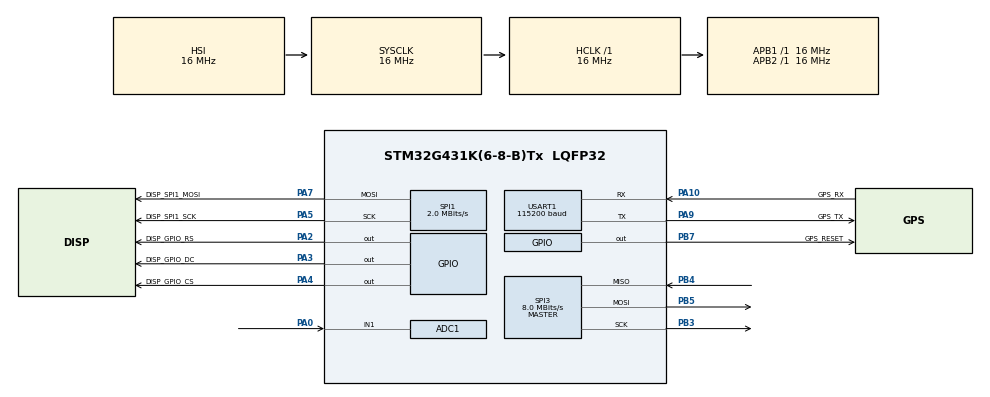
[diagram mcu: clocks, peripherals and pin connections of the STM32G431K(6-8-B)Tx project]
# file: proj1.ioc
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ADC1.Channel-0\#ChannelRegularConversion=ADC_CHANNEL_1
ADC1.NbrOfConversionFlag=1
ADC1.OffsetNumber-0\#ChannelRegularConversion=ADC_OFFSET_NONE
ADC1.Rank-0\#ChannelRegularConversion=1
ADC1.SamplingTime-0\#ChannelRegularConversion=ADC_SAMPLETIME_2CYCLES_5
ADC1.master=1
Dma.Request0=USART1_RX
Dma.USART1_RX.0.Direction=DMA_PERIPH_TO_MEMORY
Dma.USART1_RX.0.EventEnable=DISABLE
Dma.USART1_RX.0.Instance=DMA1_Channel1
Dma.USART1_RX.0.MemDataAlignment=DMA_MDATAALIGN_BYTE
Dma.USART1_RX.0.MemInc=DMA_MINC_ENABLE
Dma.USART1_RX.0.Mode=DMA_NORMAL
Dma.USART1_RX.0.PeriphDataAlignment=DMA_PDATAALIGN_BYTE
Dma.USART1_RX.0.PeriphInc=DMA_PINC_DISABLE
Dma.USART1_RX.0.Polarity=HAL_DMAMUX_REQ_GEN_RISING
Dma.USART1_RX.0.Priority=DMA_PRIORITY_LOW
Dma.USART1_RX.0.RequestNumber=1
Dma.USART1_RX.0.SignalID=NONE
Dma.USART1_RX.0.SyncEnable=DISABLE
Dma.USART1_RX.0.SyncPolarity=HAL_DMAMUX_SYNC_NO_EVENT
Dma.USART1_RX.0.SyncRequestNumber=1
Dma.USART1_RX.0.SyncSignalID=NONE
Mcu.Family=STM32G4
Mcu.Name=STM32G431K(6-8-B)Tx
Mcu.Package=LQFP32
NVIC.DMA1_Channel1_IRQn=true\:0\:0\:false\:false\:true\:false\:true\:true
NVIC.PriorityGroup=NVIC_PRIORITYGROUP_4
NVIC.USART1_IRQn=true\:0\:0\:false\:false\:true\:true\:true\:true
PA0.Mode=IN1-Single-Ended
PA0.Signal=ADC1_IN1
PA10.GPIO_Label=GPS_RX
PA10.Mode=Asynchronous
PA10.Signal=USART1_RX
PA13.Mode=Serial_Wire
PA13.Signal=SYS_JTMS-SWDIO
PA14.Mode=Serial_Wire
PA14.Signal=SYS_JTCK-SWCLK
PA2.GPIO_Label=DISP_GPIO_RS
PA2.Signal=GPIO_Output
PA3.GPIO_Label=DISP_GPIO_DC
PA3.Signal=GPIO_Output
PA4.GPIO_Label=DISP_GPIO_CS
PA4.Signal=GPIO_Output
PA5.GPIO_Label=DISP_SPI1_SCK
PA5.Mode=TX_Only_Simplex_Unidirect_Master
PA5.Signal=SPI1_SCK
PA7.GPIO_Label=DISP_SPI1_MOSI
PA7.Mode=TX_Only_Simplex_Unidirect_Master
PA7.Signal=SPI1_MOSI
PA9.GPIO_Label=GPS_TX
PA9.Mode=Asynchronous
PA9.Signal=USART1_TX
PB3.Mode=Full_Duplex_Master
PB3.Signal=SPI3_SCK
PB4.Mode=Full_Duplex_Master
PB4.Signal=SPI3_MISO
PB5.Mode=Full_Duplex_Master
PB5.Signal=SPI3_MOSI
PB7.GPIO_Label=GPS_RESET
PB7.Signal=GPIO_Output
ProjectManager.HeapSize=0x200
ProjectManager.StackSize=0x400
ProjectManager.TargetToolchain=STM32CubeIDE
RCC.AHBFreq_Value=16000000
RCC.APB1Freq_Value=16000000
RCC.APB1TimFreq_Value=16000000
RCC.APB2Freq_Value=16000000
RCC.APB2TimFreq_Value=16000000
RCC.CortexFreq_Value=16000000
RCC.EXTERNAL_CLOCK_VALUE=12288000
RCC.HCLKFreq_Value=16000000
RCC.HSE_VALUE=8000000
RCC.HSI48_VALUE=48000000
RCC.HSI_VALUE=16000000
RCC.LSE_VALUE=32768
RCC.SYSCLKFreq_VALUE=16000000
RCC.USBFreq_Value=64000000
RCC.VCOOutputFreq_Value=128000000
SPI1.BaudRatePrescaler=SPI_BAUDRATEPRESCALER_8
SPI1.CLKPhase=SPI_PHASE_2EDGE
SPI1.CLKPolarity=SPI_POLARITY_HIGH
SPI1.CalculateBaudRate=2.0 MBits/s
SPI1.DataSize=SPI_DATASIZE_8BIT
SPI1.Direction=SPI_DIRECTION_2LINES
SPI1.Mode=SPI_MODE_MASTER
SPI1.VirtualType=VM_MASTER
SPI3.CalculateBaudRate=8.0 MBits/s
SPI3.Direction=SPI_DIRECTION_2LINES
SPI3.Mode=SPI_MODE_MASTER
SPI3.VirtualType=VM_MASTER
USART1.BaudRate=115200
USART1.VirtualMode-Asynchronous=VM_ASYNC
VP_SYS_VS_DBSignals.Mode=DisableDeadBatterySignals
board=custom

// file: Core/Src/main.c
/* USER CODE BEGIN Header */
/**
  ******************************************************************************
  * @file           : main.c
  * @brief          : Main program body
  ******************************************************************************
  * @attention
  *
  * Copyright (c) 2025 STMicroelectronics.
  * All rights reserved.
  *
  * This software is licensed under terms that can be found in the LICENSE file
  * in the root directory of this software component.
  * If no LICENSE file comes with this software, it is provided AS-IS.
  *
  ******************************************************************************
  */
/* USER CODE END Header */
#include "main.h"
#include "display.h"
#include "gps.h"
#include "text.h"
#include "utils.h"

ADC_HandleTypeDef hadc1;

SPI_HandleTypeDef hspi1;
SPI_HandleTypeDef hspi3;

UART_HandleTypeDef huart1;
DMA_HandleTypeDef hdma_usart1_rx;

void SystemClock_Config(void);
static void MX_GPIO_Init(void);
static void MX_DMA_Init(void);
static void MX_ADC1_Init(void);
static void MX_SPI1_Init(void);
static void MX_SPI3_Init(void);
static void MX_USART1_UART_Init(void);

int main(void)
{

  /* MCU Configuration--------------------------------------------------------*/

  /* Reset of all peripherals, Initializes the Flash interface and the Systick. */
  HAL_Init();

  /* Configure the system clock */
  SystemClock_Config();

  /* Initialize all configured peripherals */
  MX_GPIO_Init();
  MX_DMA_Init();
  MX_ADC1_Init();
  MX_SPI1_Init();
  MX_SPI3_Init();
  MX_USART1_UART_Init();
  /* USER CODE BEGIN 2 */

  display_setup();

  display_clear();
  buffer_clear();

  origin_set(0, 0);

  writestr("GPS SUBSYS START..");
  initializeGPS();
  display_update();

  startAsyncReceive(1);
  /* USER CODE END 2 */

  /* Infinite loop */
  while (1)
  {
	  maincall();
  }
}

void SystemClock_Config(void)
{
  RCC_OscInitTypeDef RCC_OscInitStruct = {0};
  RCC_ClkInitTypeDef RCC_ClkInitStruct = {0};

  /** Configure the main internal regulator output voltage
  */
  HAL_PWREx_ControlVoltageScaling(PWR_REGULATOR_VOLTAGE_SCALE1);

  /** Initializes the RCC Oscillators according to the specified parameters
  * in the RCC_OscInitTypeDef structure.
  */
  RCC_OscInitStruct.OscillatorType = RCC_OSCILLATORTYPE_HSI;
  RCC_OscInitStruct.HSIState = RCC_HSI_ON;
  RCC_OscInitStruct.HSICalibrationValue = RCC_HSICALIBRATION_DEFAULT;
  RCC_OscInitStruct.PLL.PLLState = RCC_PLL_NONE;
  if (HAL_RCC_OscConfig(&RCC_OscInitStruct) != HAL_OK)
  {
    Error_Handler();
  }

  /** Initializes the CPU, AHB and APB buses clocks
  */
  RCC_ClkInitStruct.ClockType = RCC_CLOCKTYPE_HCLK|RCC_CLOCKTYPE_SYSCLK
                              |RCC_CLOCKTYPE_PCLK1|RCC_CLOCKTYPE_PCLK2;
  RCC_ClkInitStruct.SYSCLKSource = RCC_SYSCLKSOURCE_HSI;
  RCC_ClkInitStruct.AHBCLKDivider = RCC_SYSCLK_DIV1;
  RCC_ClkInitStruct.APB1CLKDivider = RCC_HCLK_DIV1;
  RCC_ClkInitStruct.APB2CLKDivider = RCC_HCLK_DIV1;

  if (HAL_RCC_ClockConfig(&RCC_ClkInitStruct, FLASH_LATENCY_0) != HAL_OK)
  {
    Error_Handler();
  }
}

static void MX_ADC1_Init(void)
{

  ADC_MultiModeTypeDef multimode = {0};
  ADC_ChannelConfTypeDef sConfig = {0};

  /** Common config
  */
  hadc1.Instance = ADC1;
  hadc1.Init.ClockPrescaler = ADC_CLOCK_SYNC_PCLK_DIV2;
  hadc1.Init.Resolution = ADC_RESOLUTION_12B;
  hadc1.Init.DataAlign = ADC_DATAALIGN_RIGHT;
  hadc1.Init.GainCompensation = 0;
  hadc1.Init.ScanConvMode = ADC_SCAN_DISABLE;
  hadc1.Init.EOCSelection = ADC_EOC_SINGLE_CONV;
  hadc1.Init.LowPowerAutoWait = DISABLE;
  hadc1.Init.ContinuousConvMode = DISABLE;
  hadc1.Init.NbrOfConversion = 1;
  hadc1.Init.DiscontinuousConvMode = DISABLE;
  hadc1.Init.ExternalTrigConv = ADC_SOFTWARE_START;
  hadc1.Init.ExternalTrigConvEdge = ADC_EXTERNALTRIGCONVEDGE_NONE;
  hadc1.Init.DMAContinuousRequests = DISABLE;
  hadc1.Init.Overrun = ADC_OVR_DATA_PRESERVED;
  hadc1.Init.OversamplingMode = DISABLE;
  if (HAL_ADC_Init(&hadc1) != HAL_OK)
  {
    Error_Handler();
  }

  /** Configure the ADC multi-mode
  */
  multimode.Mode = ADC_MODE_INDEPENDENT;
  if (HAL_ADCEx_MultiModeConfigChannel(&hadc1, &multimode) != HAL_OK)
  {
    Error_Handler();
  }

  /** Configure Regular Channel
  */
  sConfig.Channel = ADC_CHANNEL_1;
  sConfig.Rank = ADC_REGULAR_RANK_1;
  sConfig.SamplingTime = ADC_SAMPLETIME_2CYCLES_5;
  sConfig.SingleDiff = ADC_SINGLE_ENDED;
  sConfig.OffsetNumber = ADC_OFFSET_NONE;
  sConfig.Offset = 0;
  if (HAL_ADC_ConfigChannel(&hadc1, &sConfig) != HAL_OK)
  {
    Error_Handler();
  }

}

static void MX_SPI1_Init(void)
{

  /* SPI1 parameter configuration*/
  hspi1.Instance = SPI1;
  hspi1.Init.Mode = SPI_MODE_MASTER;
  hspi1.Init.Direction = SPI_DIRECTION_2LINES;
  hspi1.Init.DataSize = SPI_DATASIZE_8BIT;
  hspi1.Init.CLKPolarity = SPI_POLARITY_HIGH;
  hspi1.Init.CLKPhase = SPI_PHASE_2EDGE;
  hspi1.Init.NSS = SPI_NSS_SOFT;
  hspi1.Init.BaudRatePrescaler = SPI_BAUDRATEPRESCALER_8;
  hspi1.Init.FirstBit = SPI_FIRSTBIT_MSB;
  hspi1.Init.TIMode = SPI_TIMODE_DISABLE;
  hspi1.Init.CRCCalculation = SPI_CRCCALCULATION_DISABLE;
  hspi1.Init.CRCPolynomial = 7;
  hspi1.Init.CRCLength = SPI_CRC_LENGTH_DATASIZE;
  hspi1.Init.NSSPMode = SPI_NSS_PULSE_DISABLE;
  if (HAL_SPI_Init(&hspi1) != HAL_OK)
  {
    Error_Handler();
  }

}

static void MX_SPI3_Init(void)
{

  /* SPI3 parameter configuration*/
  hspi3.Instance = SPI3;
  hspi3.Init.Mode = SPI_MODE_MASTER;
  hspi3.Init.Direction = SPI_DIRECTION_2LINES;
  hspi3.Init.DataSize = SPI_DATASIZE_4BIT;
  hspi3.Init.CLKPolarity = SPI_POLARITY_LOW;
  hspi3.Init.CLKPhase = SPI_PHASE_1EDGE;
  hspi3.Init.NSS = SPI_NSS_SOFT;
  hspi3.Init.BaudRatePrescaler = SPI_BAUDRATEPRESCALER_2;
  hspi3.Init.FirstBit = SPI_FIRSTBIT_MSB;
  hspi3.Init.TIMode = SPI_TIMODE_DISABLE;
  hspi3.Init.CRCCalculation = SPI_CRCCALCULATION_DISABLE;
  hspi3.Init.CRCPolynomial = 7;
  hspi3.Init.CRCLength = SPI_CRC_LENGTH_DATASIZE;
  hspi3.Init.NSSPMode = SPI_NSS_PULSE_ENABLE;
  if (HAL_SPI_Init(&hspi3) != HAL_OK)
  {
    Error_Handler();
  }

}

static void MX_USART1_UART_Init(void)
{

  huart1.Instance = USART1;
  huart1.Init.BaudRate = 115200;
  huart1.Init.WordLength = UART_WORDLENGTH_8B;
  huart1.Init.StopBits = UART_STOPBITS_1;
  huart1.Init.Parity = UART_PARITY_NONE;
  huart1.Init.Mode = UART_MODE_TX_RX;
  huart1.Init.HwFlowCtl = UART_HWCONTROL_NONE;
  huart1.Init.OverSampling = UART_OVERSAMPLING_16;
  huart1.Init.OneBitSampling = UART_ONE_BIT_SAMPLE_DISABLE;
  huart1.Init.ClockPrescaler = UART_PRESCALER_DIV1;
  huart1.AdvancedInit.AdvFeatureInit = UART_ADVFEATURE_NO_INIT;
  if (HAL_UART_Init(&huart1) != HAL_OK)
  {
    Error_Handler();
  }
  if (HAL_UARTEx_SetTxFifoThreshold(&huart1, UART_TXFIFO_THRESHOLD_1_8) != HAL_OK)
  {
    Error_Handler();
  }
  if (HAL_UARTEx_SetRxFifoThreshold(&huart1, UART_RXFIFO_THRESHOLD_1_8) != HAL_OK)
  {
    Error_Handler();
  }
  if (HAL_UARTEx_DisableFifoMode(&huart1) != HAL_OK)
  {
    Error_Handler();
  }

}

static void MX_DMA_Init(void)
{

  /* DMA controller clock enable */
  __HAL_RCC_DMAMUX1_CLK_ENABLE();
  __HAL_RCC_DMA1_CLK_ENABLE();

  /* DMA interrupt init */
  /* DMA1_Channel1_IRQn interrupt configuration */
  HAL_NVIC_SetPriority(DMA1_Channel1_IRQn, 0, 0);
  HAL_NVIC_EnableIRQ(DMA1_Channel1_IRQn);

}

static void MX_GPIO_Init(void)
{
  GPIO_InitTypeDef GPIO_InitStruct = {0};

  /* GPIO Ports Clock Enable */
  __HAL_RCC_GPIOA_CLK_ENABLE();
  __HAL_RCC_GPIOB_CLK_ENABLE();

  /*Configure GPIO pin Output Level */
  HAL_GPIO_WritePin(GPIOA, DISP_GPIO_RS_Pin|DISP_GPIO_DC_Pin|DISP_GPIO_CS_Pin, GPIO_PIN_RESET);

  /*Configure GPIO pin Output Level */
  HAL_GPIO_WritePin(GPS_RESET_GPIO_Port, GPS_RESET_Pin, GPIO_PIN_RESET);

  /*Configure GPIO pins : DISP_GPIO_RS_Pin DISP_GPIO_DC_Pin DISP_GPIO_CS_Pin */
  GPIO_InitStruct.Pin = DISP_GPIO_RS_Pin|DISP_GPIO_DC_Pin|DISP_GPIO_CS_Pin;
  GPIO_InitStruct.Mode = GPIO_MODE_OUTPUT_PP;
  GPIO_InitStruct.Pull = GPIO_NOPULL;
  GPIO_InitStruct.Speed = GPIO_SPEED_FREQ_LOW;
  HAL_GPIO_Init(GPIOA, &GPIO_InitStruct);

  /*Configure GPIO pin : GPS_RESET_Pin */
  GPIO_InitStruct.Pin = GPS_RESET_Pin;
  GPIO_InitStruct.Mode = GPIO_MODE_OUTPUT_PP;
  GPIO_InitStruct.Pull = GPIO_NOPULL;
  GPIO_InitStruct.Speed = GPIO_SPEED_FREQ_LOW;
  HAL_GPIO_Init(GPS_RESET_GPIO_Port, &GPIO_InitStruct);

}

/* USER CODE BEGIN 4 */
//callback is called whenever the cpu is finished receiving a uart message
void HAL_UART_RxCpltCallback(UART_HandleTypeDef *huart)
{
  startAsyncReceive(0);

}
/* USER CODE END 4 */

void Error_Handler(void)
{
  __disable_irq();
  while (1)
  {
  }
}
